AUTOSAR XML (schema 00049)
package /Components
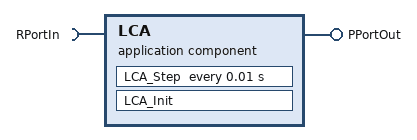
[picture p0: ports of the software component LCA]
  application sw component type LCA
    require port RPortIn: required-interface=RPortIn
      required-com-specs:
        data-element=Highway_Input_Signal, alive-timeout=30, init-value=0
        data-element=Lane_Input_Signal, alive-timeout=30, init-value=0
        data-element=Input_Switch, alive-timeout=30, init-value=0
        data-element=Enable_Display, alive-timeout=30, init-value=0
    provide port PPortOut: provided-interface=PPortOut
      provided-com-specs:
        data-element=Display_Mode_{1..4}, init-value=0
    behavior LCA_IB: handle-termination-and-restart=NO-SUPPORT
      timing event Event_LCA_Step: start-on-event=LCA_Step, period=0.01
      runnable LCA_Init
      runnable LCA_Step
        data-receive-point-by-values:
          4 x access:
            IN_RPortIn_Highway_Input_Signal: accessed-variable=RPortIn.Highway_Input_Signal
            IN_RPortIn_Enable_Display: accessed-variable=RPortIn.Enable_Display
            IN_RPortIn_Input_Switch: accessed-variable=RPortIn.Input_Switch
            IN_RPortIn_Lane_Input_Signal: accessed-variable=RPortIn.Lane_Input_Signal
        data-send-points:
          4 x access:
            OUT_PPortOut_Display_Mode_{1..4}: accessed-variable=PPortOut.Display_Mode_{1..4}
